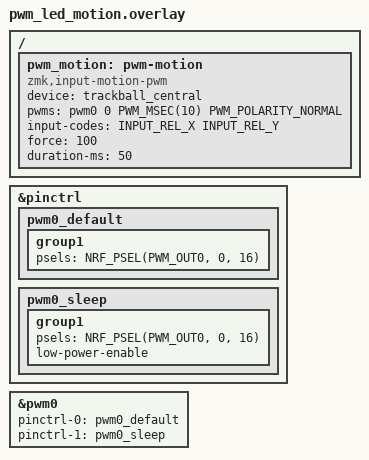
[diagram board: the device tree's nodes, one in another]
#include <zephyr/dt-bindings/pwm/pwm.h>
#include <zephyr/dt-bindings/input/input-event-codes.h>

&pinctrl {
    pwm0_default: pwm0_default {
        group1 {
            psels = <NRF_PSEL(PWM_OUT0, 0, 16)>;
        };
    };

    pwm0_sleep: pwm0_sleep {
        group1 {
            psels = <NRF_PSEL(PWM_OUT0, 0, 16)>;
            low-power-enable;
        };
    };
};

/ {
    pwm_motion: pwm-motion {
        compatible = "zmk,input-motion-pwm";
        device = <&trackball_central>;
        pwms = <&pwm0 0 PWM_MSEC(10) PWM_POLARITY_NORMAL>;
        input-codes = <INPUT_REL_X INPUT_REL_Y>;
        force = <100>;
        duration-ms = <50>;
    };
};

&pwm0 {
    status = "okay";
    pinctrl-0 = <&pwm0_default>;
    pinctrl-1 = <&pwm0_sleep>;
    pinctrl-names = "default", "sleep";
};
